# f28p65x_gpio_data_regs register map
Vendor: Texas Instruments
Peripheral module from a debugger description file (folder C2000).
Address unit: 16 bits
Registers are 32-bit, read-write, no defined reset value unless marked. A register's access mark holds for its fields unless they carry their own. Offsets are as the file gives them; lines under a group give offsets from that group; [hi:lo] are bit positions; {n}, {i} and the like mark numbered series; 'fields as' and 'values as' point back to an identical list; <NAME> marks a mode.

## GPIO_DATA_REGS — GPIO DATA Registers
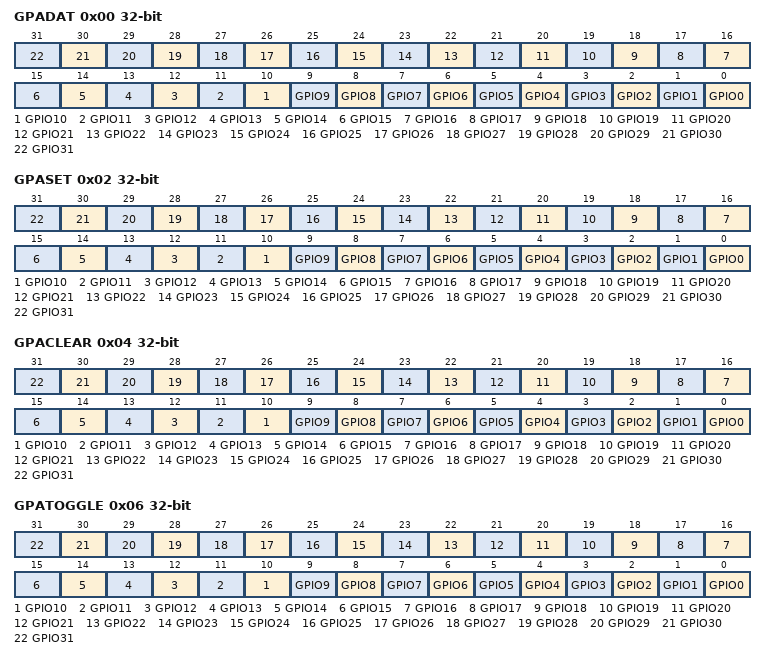
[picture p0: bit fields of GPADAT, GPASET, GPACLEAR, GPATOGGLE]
0x00 GPADAT — GPIO A Data Register (GPIO0 to 31)
  [n] GPIO{n} (n=0..31) — Data Register for this pin
0x02 GPASET — GPIO A Data Set Register (GPIO0 to 31)
  [n] GPIO{n} (n=0..31) — Output Set bit for this pin
0x04 GPACLEAR — GPIO A Data Clear Register (GPIO0 to 31)
  [n] GPIO{n} (n=0..31) — Output Clear bit for this pin
0x06 GPATOGGLE — GPIO A Data Toggle Register (GPIO0 to 31)
  [n] GPIO{n} (n=0..31) — Output Toggle bit for this pin
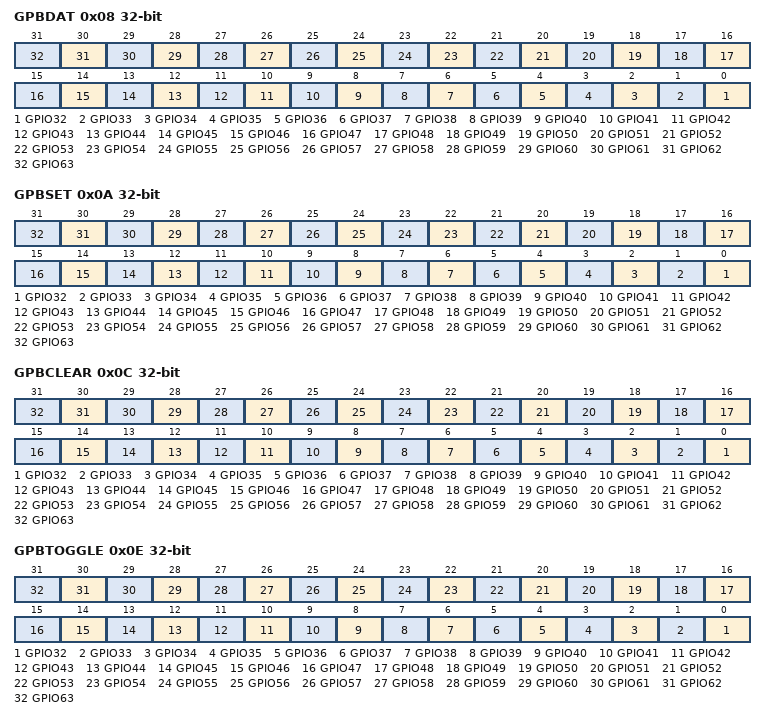
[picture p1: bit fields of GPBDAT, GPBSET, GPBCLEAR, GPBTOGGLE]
0x08 GPBDAT — GPIO B Data Register (GPIO32 to 63)
  [n-32] GPIO{n} (n=32..63) — Data Register for this pin
0x0A GPBSET — GPIO B Data Set Register (GPIO32 to 63)
  [n-32] GPIO{n} (n=32..63) — Output Set bit for this pin
0x0C GPBCLEAR — GPIO B Data Clear Register (GPIO32 to 63)
  [n-32] GPIO{n} (n=32..63) — Output Clear bit for this pin
0x0E GPBTOGGLE — GPIO B Data Toggle Register (GPIO32 to 63)
  [n-32] GPIO{n} (n=32..63) — Output Toggle bit for this pin
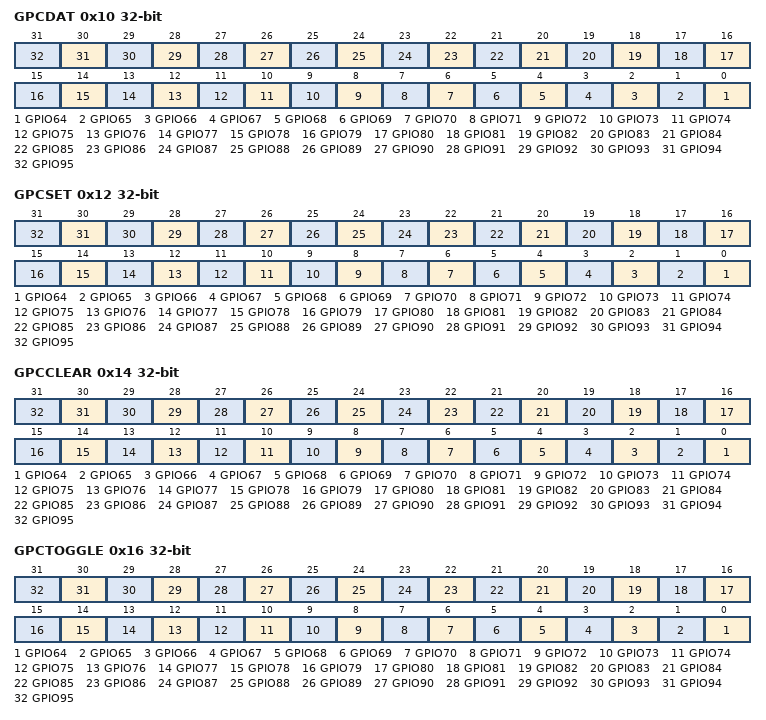
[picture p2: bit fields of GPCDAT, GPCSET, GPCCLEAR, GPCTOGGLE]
0x10 GPCDAT — GPIO C Data Register (GPIO64 to 95)
  [n-64] GPIO{n} (n=64..95) — Data Register for this pin
0x12 GPCSET — GPIO C Data Set Register (GPIO64 to 95)
  [n-64] GPIO{n} (n=64..95) — Output Set bit for this pin
0x14 GPCCLEAR — GPIO C Data Clear Register (GPIO64 to 95)
  [n-64] GPIO{n} (n=64..95) — Output Clear bit for this pin
0x16 GPCTOGGLE — GPIO C Data Toggle Register (GPIO64 to 95)
  [n-64] GPIO{n} (n=64..95) — Output Toggle bit for this pin
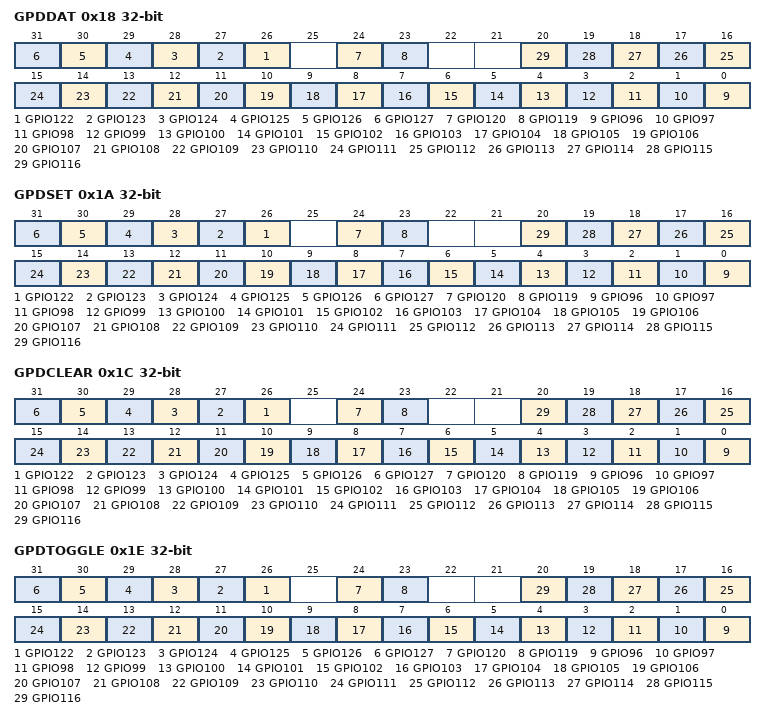
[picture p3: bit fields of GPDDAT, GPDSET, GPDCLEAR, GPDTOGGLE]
0x18 GPDDAT — GPIO D Data Register (GPIO96 to 127)
  [n-96] GPIO{n} (n=122..127) — Data Register for this pin
  [24] GPIO120 — Data Register for this pin
  [23] GPIO119 — Data Register for this pin
  [n-96] GPIO{n} (n=96..116) — Data Register for this pin
0x1A GPDSET — GPIO D Data Set Register (GPIO96 to 127)
  [n-96] GPIO{n} (n=122..127) — Output Set bit for this pin
  [24] GPIO120 — Output Set bit for this pin
  [23] GPIO119 — Output Set bit for this pin
  [n-96] GPIO{n} (n=96..116) — Output Set bit for this pin
0x1C GPDCLEAR — GPIO D Data Clear Register (GPIO96 to 127)
  [n-96] GPIO{n} (n=122..127) — Output Clear bit for this pin
  [24] GPIO120 — Output Clear bit for this pin
  [23] GPIO119 — Output Clear bit for this pin
  [n-96] GPIO{n} (n=96..116) — Output Clear bit for this pin
0x1E GPDTOGGLE — GPIO D Data Toggle Register (GPIO96 to 127)
  [n-96] GPIO{n} (n=122..127) — Output Toggle bit for this pin
  [24] GPIO120 — Output Toggle bit for this pin
  [23] GPIO119 — Output Toggle bit for this pin
  [n-96] GPIO{n} (n=96..116) — Output Toggle bit for this pin
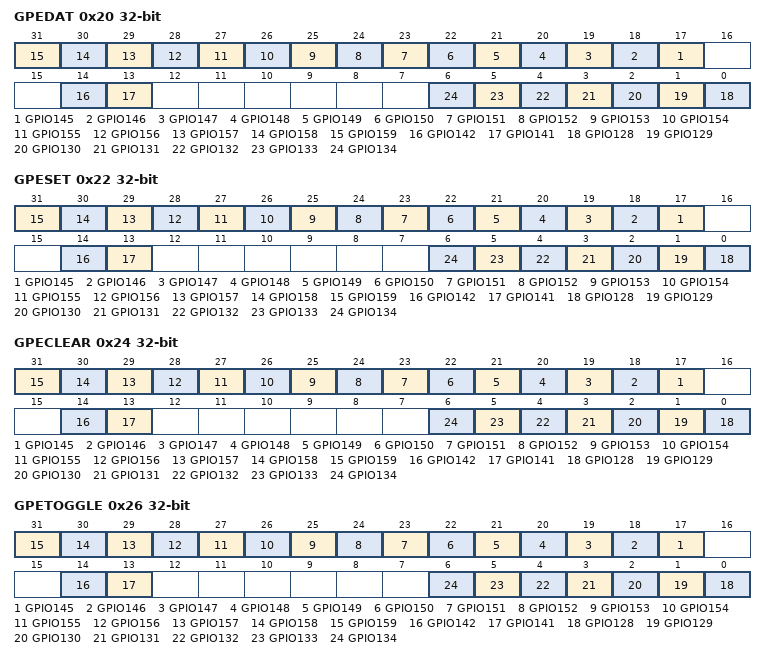
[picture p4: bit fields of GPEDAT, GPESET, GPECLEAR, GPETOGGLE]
0x20 GPEDAT — GPIO E Data Register (GPIO128 to 159)
  [n-128] GPIO{n} (n=145..159) — Data Register for this pin
  [14] GPIO142 — Data Register for this pin
  [13] GPIO141 — Data Register for this pin
  [n-128] GPIO{n} (n=128..134) — Data Register for this pin
0x22 GPESET — GPIO E Data Set Register (GPIO128 to 159)
  [n-128] GPIO{n} (n=145..159) — Output Set bit for this pin
  [14] GPIO142 — Output Set bit for this pin
  [13] GPIO141 — Output Set bit for this pin
  [n-128] GPIO{n} (n=128..134) — Output Set bit for this pin
0x24 GPECLEAR — GPIO E Data Clear Register (GPIO128 to 159)
  [n-128] GPIO{n} (n=145..159) — Output Clear bit for this pin
  [14] GPIO142 — Output Clear bit for this pin
  [13] GPIO141 — Output Clear bit for this pin
  [n-128] GPIO{n} (n=128..134) — Output Clear bit for this pin
0x26 GPETOGGLE — GPIO E Data Toggle Register (GPIO128 to 159)
  [n-128] GPIO{n} (n=145..159) — Output Toggle bit for this pin
  [14] GPIO142 — Output Toggle bit for this pin
  [13] GPIO141 — Output Toggle bit for this pin
  [n-128] GPIO{n} (n=128..134) — Output Toggle bit for this pin
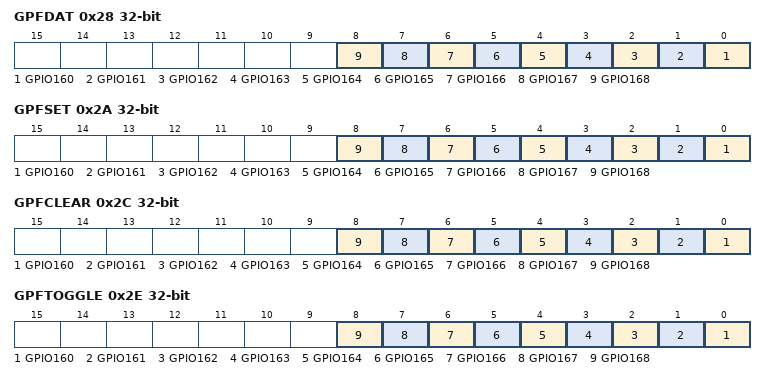
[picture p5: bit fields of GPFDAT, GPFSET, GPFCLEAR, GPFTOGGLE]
0x28 GPFDAT — GPIO F Data Register (GPIO160 to 191)
  [n-160] GPIO{n} (n=160..168) — Data Register for this pin
0x2A GPFSET — GPIO F Data Set Register (GPIO160 to 191)
  [n-160] GPIO{n} (n=160..168) — Output Set bit for this pin
0x2C GPFCLEAR — GPIO F Data Clear Register (GPIO160 to 191)
  [n-160] GPIO{n} (n=160..168) — Output Clear bit for this pin
0x2E GPFTOGGLE — GPIO F Data Toggle Register (GPIO160 to 191)
  [n-160] GPIO{n} (n=160..168) — Output Toggle bit for this pin
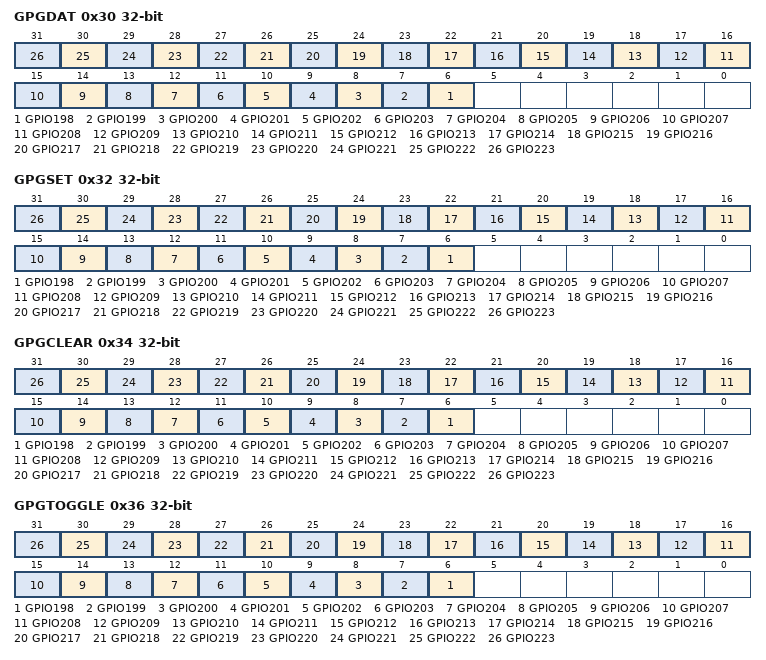
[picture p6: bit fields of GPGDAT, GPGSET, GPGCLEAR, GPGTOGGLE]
0x30 GPGDAT — GPIO G Data Register (GPIO192 to 223)
  [n-192] GPIO{n} (n=198..223) — Data Register for this pin
0x32 GPGSET — GPIO G Data Set Register (GPIO192 to 223)
  [n-192] GPIO{n} (n=198..223) — Output Set bit for this pin
0x34 GPGCLEAR — GPIO G Data Clear Register (GPIO192 to 223)
  [n-192] GPIO{n} (n=198..223) — Output Clear bit for this pin
0x36 GPGTOGGLE — GPIO G Data Toggle Register (GPIO192 to 223)
  [n-192] GPIO{n} (n=198..223) — Output Toggle bit for this pin
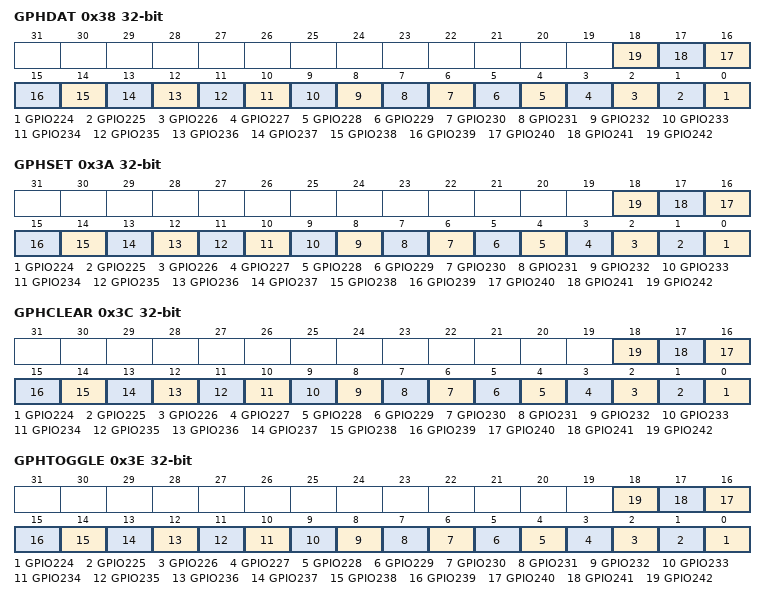
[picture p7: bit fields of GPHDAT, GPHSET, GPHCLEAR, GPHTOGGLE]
0x38 GPHDAT — GPIO H Data Register (GPIO224 to 255)
  [n-224] GPIO{n} (n=224..242) — Data Register for this pin
0x3A GPHSET — GPIO H Data Set Register (GPIO224 to 255)
  [n-224] GPIO{n} (n=224..242) — Output Set bit for this pin
0x3C GPHCLEAR — GPIO H Data Clear Register (GPIO224 to 255)
  [n-224] GPIO{n} (n=224..242) — Output Clear bit for this pin
0x3E GPHTOGGLE — GPIO H Data Toggle Register (GPIO224 to 255)
  [n-224] GPIO{n} (n=224..242) — Output Toggle bit for this pin
